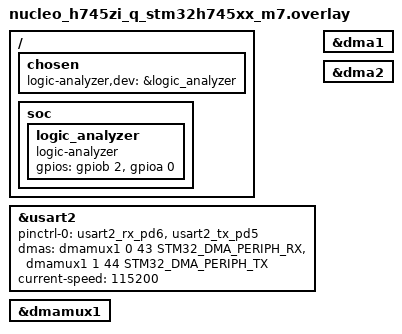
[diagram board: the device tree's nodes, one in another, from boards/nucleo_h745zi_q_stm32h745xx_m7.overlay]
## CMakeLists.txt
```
cmake_minimum_required(VERSION 3.20.0)
find_package(Zephyr REQUIRED HINTS $ENV{ZEPHYR_BASE})
project(logic-analyzer-test)

target_sources(app PRIVATE src/main.cpp)
```

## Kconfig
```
menuconfig LOGIC_ANALYZER
    bool "Enable LogicAnalyzer module"
    select SERIAL
    help
      Enable LogicAnalyzer module

config LOGIC_ANALYZER_PRIO
    int "Set the module priority"
    default 0
    help
      Set the Logic Analyzer module priority
```

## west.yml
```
manifest:
  defaults:
    remote: zephyr

  remotes:
    - name: zephyr
      url-base: https://github.com/zephyrproject-rtos

  projects:
    - name: zephyr
      revision: 781011b911736ad94a8d7ebde24ceae3998bc03f
      path: zephyr
      west-commands: scripts/west-commands.yml
    - name: hal_stm32
      revision: 46c5ca5ac099ac1ed530975ea2bb5dc4ebb4dfb2
      path: modules/hal/stm32
      groups:
        - hal
    - name: cmsis
      revision: d1b8b20b6278615b00e136374540eb1c00dcabe7
      path: modules/hal/cmsis
      groups:
        - hal
    - name: LogicAnalyzer
      url: git@github.com:drog-drog/LogicAnalyzer.git
      revision: v1.0.0
      path: LogicAnalyzer
```

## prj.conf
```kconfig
# CPP
CONFIG_CPP=y
CONFIG_STD_CPP20=y

# Logic Analyzer
CONFIG_GPIO=y
CONFIG_LOGIC_ANALYZER=y

# UART
CONFIG_SERIAL=y
CONFIG_UART_ASYNC_API=y

# Other
CONFIG_DCACHE=n
```

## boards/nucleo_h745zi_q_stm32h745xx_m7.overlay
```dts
/ {

    chosen{
        logic-analyzer,dev = &logic_analyzer;
    };

    soc{
        logic_analyzer: logic_analyzer{
            compatible = "logic-analyzer";
            gpios = <&gpiob 2 GPIO_ACTIVE_HIGH>, <&gpioa 0 GPIO_ACTIVE_HIGH>;
        };
    };

};

&usart2 {
    pinctrl-0 = <&usart2_rx_pd6 &usart2_tx_pd5>;
    dmas = <&dmamux1 0 43 STM32_DMA_PERIPH_RX>,
        <&dmamux1 1 44 STM32_DMA_PERIPH_TX>;
    dma-names = "rx", "tx";
    pinctrl-names = "default";
    current-speed = <115200>;
    status = "okay";
};

&dmamux1 {
    status = "okay";
};

&dma1 {
    status = "okay";
};

&dma2 {
    status = "okay";
};
```

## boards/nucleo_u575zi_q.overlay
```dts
/ {

    chosen{
        logic-analyzer,dev = &logic_analyzer;
    };

    soc{
        logic_analyzer: logic_analyzer{
            compatible = "logic-analyzer";
            gpios = <&gpiob 2 GPIO_ACTIVE_HIGH>, <&gpioa 0 GPIO_ACTIVE_HIGH>;
        };
    };

};

&usart2 {
    pinctrl-0 = <&usart2_rx_pd6 &usart2_tx_pd5>;
    pinctrl-names = "default";
    current-speed = <115200>;
    hw-flow-control;
    status = "okay";
};
```

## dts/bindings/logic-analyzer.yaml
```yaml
description: |
  This is the binding for the logic analyzer node.
  It dosent require much. only its pins.

compatible: "logic-analyzer"

properties:
  gpios:
    type: phandle-array
    required: true
    description: |
      These are the pins that will be sampled
```

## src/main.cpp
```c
#include <zephyr/kernel.h>
#include <LogicAnalyzer.hpp>

#define GPIO_NODE DT_NODELABEL(logic_analyzer)
#define GPIO_COUNT DT_PROP_LEN(GPIO_NODE, gpios)
#define INIT_GPIO(idx, _) GPIO_DT_SPEC_GET_BY_IDX(GPIO_NODE, gpios, idx),
struct gpio_dt_spec gpio_list[GPIO_COUNT] = {
    LISTIFY(GPIO_COUNT, INIT_GPIO, ())
};

int main(){
    struct device* serial_dev = const_cast<struct device*>(DEVICE_DT_GET(DT_NODELABEL(usart2)));
    LogicAnalyzer* analyzer = NULL;

    analyzer = LogicAnalyzer::instance_init(serial_dev, gpio_list, GPIO_COUNT);
    analyzer->start_capture();

    return 0;
}
```

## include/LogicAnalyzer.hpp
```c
#include <zephyr/device.h>
#include <zephyr/drivers/gpio.h>

class LogicAnalyzer{
public:
    static LogicAnalyzer* instance_init(struct device* serial_dev, struct gpio_dt_spec* pins, size_t size);

    /* Default big 5 */
    LogicAnalyzer(LogicAnalyzer&) noexcept = default;
    LogicAnalyzer(LogicAnalyzer&&) noexcept = default;
    LogicAnalyzer& operator=(LogicAnalyzer&) noexcept = default;
    LogicAnalyzer& operator=(LogicAnalyzer&&) noexcept = default;
    virtual ~LogicAnalyzer() = default;

    /* Setters */
    void set_pins(struct gpio_dt_spec* pins, size_t size);
    void set_serial_dev(struct device* serial_dev);

    int start_capture();
    int stop_capture();
    
    /* Callback handlers */
    void sync_serial(struct uart_event *evt);
    void start_output();
    
private:
    /* Analyzer sources for output */
    struct gpio_dt_spec* _gpio_pins;
    size_t _gpio_pins_count;
    struct device* _serial_dev;
    struct k_mutex _serial_sync;
    
    /* Output thread */
    struct k_thread _output_thread;
    
    
    /* Ctor */
    LogicAnalyzer(struct device* serial_dev, struct gpio_dt_spec* pins, size_t size);
    
    static void logic_analyzer_output(void* _gpio_pins, void* size, void* none);
    
    static void serial_cb(const struct device *dev, struct uart_event *evt, void *user_data);
};
```

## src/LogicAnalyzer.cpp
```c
#include <string.h>

#include <zephyr/kernel.h>
#include <zephyr/drivers/uart.h>
#include <zephyr/logging/log.h>

#include "LogicAnalyzer.hpp"

LOG_MODULE_REGISTER(Logic_Analyzer);

constexpr int THREAD_SIZE = 2048;
constexpr int OUTPUT_STR_SIZE = 13;
constexpr uint8_t ANSII_CLEAR_CONSOLE[] = "\x1B[2J";
constexpr uint8_t ANSII_CONSOLE_BEGINNING[] = "\x1B[H";

__nocache char pin_stat[OUTPUT_STR_SIZE] = { 0 };

K_THREAD_STACK_DEFINE(output_thread_stack, THREAD_SIZE);

LogicAnalyzer* LogicAnalyzer::instance_init(struct device* serial_dev, struct gpio_dt_spec* pins, size_t size){
    static LogicAnalyzer instance(serial_dev, pins, size);
    return &instance;
}

LogicAnalyzer::LogicAnalyzer(struct device* serial_dev, struct gpio_dt_spec* pins, size_t size){
    this->_serial_dev = serial_dev;
    this->_gpio_pins = pins;
    this->_gpio_pins_count = size;

    /* Configure pins for input */
    for(size_t i = 0; i < _gpio_pins_count;  i++){
        gpio_pin_configure_dt(&this->_gpio_pins[i], GPIO_INPUT);
    }

    /* Initiate resources for synchronic UART */
    uart_callback_set(this->_serial_dev, LogicAnalyzer::serial_cb, this);
    k_mutex_init(&this->_serial_sync);
}

void LogicAnalyzer::set_pins(struct gpio_dt_spec* pins, size_t size){
    this->_gpio_pins = pins;
    this->_gpio_pins_count = size;
}

void LogicAnalyzer::set_serial_dev(struct device* serial_dev){
    this->_serial_dev = serial_dev;
}

int LogicAnalyzer::start_capture(){
    LOG_INF("Starting Logic-Analyzer thread...\n");

    /* Starting the thread */
    k_thread_create(&this->_output_thread, &output_thread_stack[0], THREAD_SIZE, LogicAnalyzer::logic_analyzer_output, 
        this, NULL, NULL, CONFIG_LOGIC_ANALYZER_PRIO, K_USER, K_NO_WAIT);
    
    k_thread_start(&this->_output_thread);
    return 0;
}

void LogicAnalyzer::serial_cb(const struct device *dev, struct uart_event *evt, void *user_data){
    LogicAnalyzer* instance = reinterpret_cast<LogicAnalyzer*>(user_data);
    instance->sync_serial(evt);
}

void LogicAnalyzer::sync_serial(struct uart_event *evt){
    switch (evt->type) {
    case UART_TX_DONE:
        k_mutex_unlock(&this->_serial_sync);
        break;
    case UART_RX_RDY:
        break;
    case UART_RX_DISABLED:
        break;
    case UART_RX_BUF_REQUEST:
        break;
    case UART_RX_BUF_RELEASED:
        break;
    case UART_RX_STOPPED:
        break;
    default:
        break;
    }
}

void LogicAnalyzer::logic_analyzer_output(void* logic_instance, void* none, void* null){
    LogicAnalyzer* instance = reinterpret_cast<LogicAnalyzer*>(logic_instance);
    instance->start_output(); 
}

void LogicAnalyzer::start_output(){
    int val = 0;
    int err = 0;
    size_t i = 0;

    while (true){
        /* Clean the entire console */
        k_mutex_lock(&this->_serial_sync, K_FOREVER);
        err = uart_tx(this->_serial_dev, ANSII_CLEAR_CONSOLE, strlen(reinterpret_cast<char*>(const_cast<uint8_t*>(ANSII_CLEAR_CONSOLE))), SYS_FOREVER_US);
        if (err < 0){
            LOG_ERR("Could not transmit ansii code of line beginning, %d\n", err);
            k_yield();
        }
        k_msleep(10);

        /* Print the values */
        for (i = 0; i < this->_gpio_pins_count; i++){
            val = gpio_pin_get_dt(&this->_gpio_pins[i]);
            LOG_INF("Read Pin %d, it's value is  %d\n", i + 1, val);

            sprintf(pin_stat, "Pin %d: %d\n\r", i + 1, val);
            
            k_mutex_lock(&this->_serial_sync, K_FOREVER);
            err = uart_tx(this->_serial_dev, reinterpret_cast<uint8_t*>(pin_stat), strlen(pin_stat), SYS_FOREVER_US);
            if (err < 0){
                LOG_ERR("Could not transmit pin state, %d\n", err);
                k_yield();
            }
            k_msleep(10);
        }

        /* Get to the console beginning */
        k_mutex_lock(&this->_serial_sync, K_FOREVER);
        err = uart_tx(this->_serial_dev, ANSII_CONSOLE_BEGINNING, strlen(reinterpret_cast<char*>(const_cast<uint8_t*>(ANSII_CONSOLE_BEGINNING))), SYS_FOREVER_US);
        if (err < 0){
            LOG_ERR("Could not transmit ansii code of line beginning, %d\n", err);
            k_yield();
        }
        k_msleep(10);

        /* Resets the pin stat */
        memset(pin_stat, 0, OUTPUT_STR_SIZE);
    }
}
```
